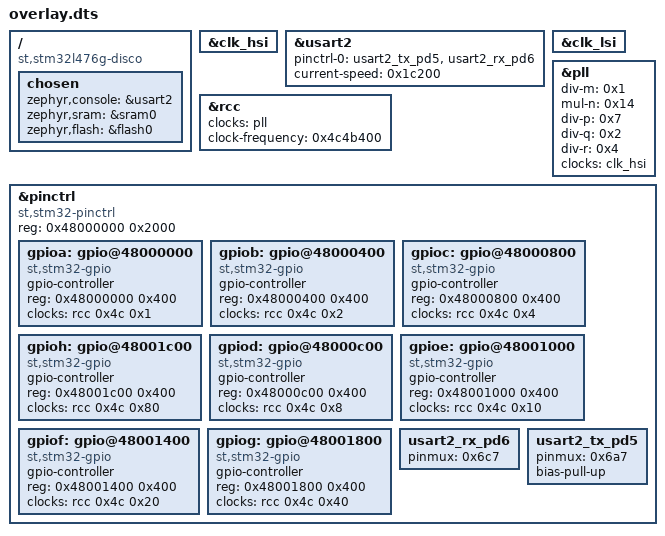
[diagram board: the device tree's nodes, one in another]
/ {
	compatible = "st,stm32l476g-disco";
	chosen {
		zephyr,console = &usart2;
		zephyr,sram = &sram0;
		zephyr,flash = &flash0;
	};
};
&clk_hsi{
	status = "okay";
};
&usart2{
	status = "okay";
	pinctrl-0 = < &usart2_tx_pd5 &usart2_rx_pd6 >;
	pinctrl-names = "default";
	current-speed = < 0x1c200 >;
};
&clk_lsi{
	status = "okay";
};
&rcc{
	clocks = < &pll >;
	clock-frequency = < 0x4c4b400 >;
};
&pll{
	status = "okay";
	div-m = < 0x1 >;
	mul-n = < 0x14 >;
	div-p = < 0x7 >;
	div-q = < 0x2 >;
	div-r = < 0x4 >;
	clocks = < &clk_hsi >;
};
&pinctrl{
	compatible = "st,stm32-pinctrl";
	#address-cells = < 0x1 >;
	#size-cells = < 0x1 >;
	reg = < 0x48000000 0x2000 >;
	gpioa: gpio@48000000 {
		compatible = "st,stm32-gpio";
		gpio-controller;
		#gpio-cells = < 0x2 >;
		reg = < 0x48000000 0x400 >;
		clocks = < &rcc 0x4c 0x1 >;
	};
	gpiob: gpio@48000400 {
		compatible = "st,stm32-gpio";
		gpio-controller;
		#gpio-cells = < 0x2 >;
		reg = < 0x48000400 0x400 >;
		clocks = < &rcc 0x4c 0x2 >;
	};
	gpioc: gpio@48000800 {
		compatible = "st,stm32-gpio";
		gpio-controller;
		#gpio-cells = < 0x2 >;
		reg = < 0x48000800 0x400 >;
		clocks = < &rcc 0x4c 0x4 >;
	};
	gpioh: gpio@48001c00 {
		compatible = "st,stm32-gpio";
		gpio-controller;
		#gpio-cells = < 0x2 >;
		reg = < 0x48001c00 0x400 >;
		clocks = < &rcc 0x4c 0x80 >;
	};
	gpiod: gpio@48000c00 {
		compatible = "st,stm32-gpio";
		gpio-controller;
		#gpio-cells = < 0x2 >;
		reg = < 0x48000c00 0x400 >;
		clocks = < &rcc 0x4c 0x8 >;
	};
	gpioe: gpio@48001000 {
		compatible = "st,stm32-gpio";
		gpio-controller;
		#gpio-cells = < 0x2 >;
		reg = < 0x48001000 0x400 >;
		clocks = < &rcc 0x4c 0x10 >;
	};
	gpiof: gpio@48001400 {
		compatible = "st,stm32-gpio";
		gpio-controller;
		#gpio-cells = < 0x2 >;
		reg = < 0x48001400 0x400 >;
		clocks = < &rcc 0x4c 0x20 >;
	};
	gpiog: gpio@48001800 {
		compatible = "st,stm32-gpio";
		gpio-controller;
		#gpio-cells = < 0x2 >;
		reg = < 0x48001800 0x400 >;
		clocks = < &rcc 0x4c 0x40 >;
	};
	usart2_rx_pd6: usart2_rx_pd6 {
		pinmux = < 0x6c7 >;
	};
	usart2_tx_pd5: usart2_tx_pd5 {
		pinmux = < 0x6a7 >;
		bias-pull-up;
	};
};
